# GENERAL_WKUP register map
Vendor: Texas Instruments
Peripheral module from a debugger description file (folder omap34xx).
Registers are 32-bit, access not given, reset 0x0 unless marked. A register's access mark holds for its fields unless they carry their own. Offsets are as the file gives them; lines under a group give offsets from that group; [hi:lo] are bit positions; {n}, {i} and the like mark numbered series; 'fields as' and 'values as' point back to an identical list; <NAME> marks a mode.

## GENERAL_WKUP
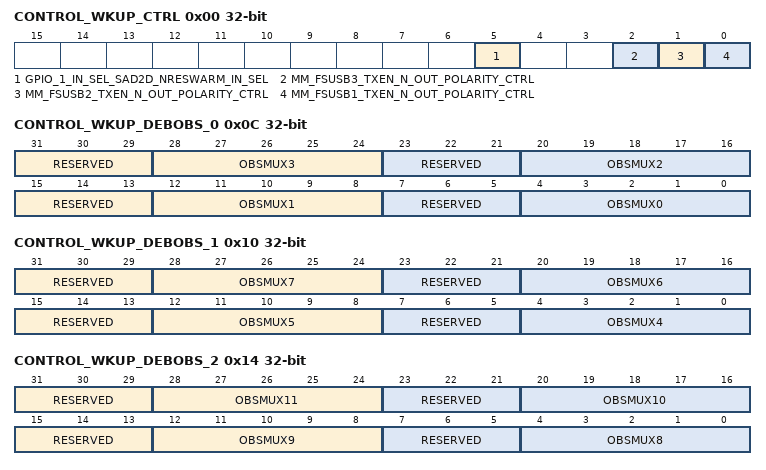
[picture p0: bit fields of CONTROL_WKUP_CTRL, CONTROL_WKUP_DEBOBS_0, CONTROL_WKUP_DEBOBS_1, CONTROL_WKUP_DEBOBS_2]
0x00 CONTROL_WKUP_CTRL access per field — USB TXEN polarity control and log modem warm reset source mux sel
  [5] GPIO_1_IN_SEL_SAD2D_NRESWARM_IN_SEL rw — Mux select for GPIO1/SAD2D_NRESWARM bit.
  [2] MM_FSUSB3_TXEN_N_OUT_POLARITY_CTRL rw — Polarity control for TXEN signal of multimode USB interface, port3.
    0=Active low; 1=Active high
  [1] MM_FSUSB2_TXEN_N_OUT_POLARITY_CTRL rw — Polarity control for TXEN signal of multimode USB interface, port2.
    0=Active low; 1=Active high
  [0] MM_FSUSB1_TXEN_N_OUT_POLARITY_CTRL rw — Polarity control for TXEN signal of multimode USB interface, port1.
    0=Active low; 1=Active high
0x0C CONTROL_WKUP_DEBOBS_0 — Select the WKUP domain set of signals to be observed for hw_dbg3, hw_dbg2, hw_dbg1, hw_dbg0
  [31:29] RESERVED ro — Read returns reset value.
  [8n+4:8n] OBSMUX{n} (n=0..3) — Select the set of signals to be observed for hw_dbg{n} (access Refer to)
  [23:21] RESERVED ro — Read returns reset value.
  [15:13] RESERVED ro — Read returns reset value.
  [7:5] RESERVED ro — Read returns reset value.
0x10 CONTROL_WKUP_DEBOBS_1 — Select the WKUP domain set of signals to be observed for hw_dbg7, hw_dbg6, hw_dbg5, hw_dbg4
  [31:29] RESERVED ro — Read returns reset value.
  [8n-28:8n-32] OBSMUX{n} (n=4..7) — Select the set of signals to be observed for hw_dbg{n} (access Refer to)
  [23:21] RESERVED ro — Read returns reset value.
  [15:13] RESERVED ro — Read returns reset value.
  [7:5] RESERVED ro — Read returns reset value.
0x14 CONTROL_WKUP_DEBOBS_2 — Select the WKUP domain set of signals to be observed for hw_dbg11 hw_dbg10, hw_dbg9, hw_dbg8
  [31:29] RESERVED ro — Read returns reset value.
  [8n-60:8n-64] OBSMUX{n} (n=8..11) — Select the set of signals to be observed for hw_dbg{n} (access Refer to)
  [23:21] RESERVED ro — Read returns reset value.
  [15:13] RESERVED ro — Read returns reset value.
  [7:5] RESERVED ro — Read returns reset value.
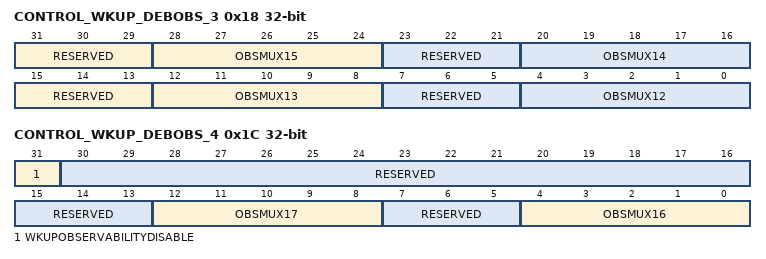
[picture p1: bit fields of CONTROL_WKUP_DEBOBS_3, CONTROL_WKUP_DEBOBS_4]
0x18 CONTROL_WKUP_DEBOBS_3 — Select the WKUP domain set of signals to be observed for hw_dbg15 hw_dbg14, hw_dbg13, hw_dbg12
  [31:29] RESERVED ro — Read returns reset value.
  [8n-92:8n-96] OBSMUX{n} (n=12..15) — Select the set of signals to be observed for hw_dbg{n} (access Refer to)
  [23:21] RESERVED ro — Read returns reset value.
  [15:13] RESERVED ro — Read returns reset value.
  [7:5] RESERVED ro — Read returns reset value.
0x1C CONTROL_WKUP_DEBOBS_4 — Select the WKUP domain set of signals to be observed for hw_dbg17, hw_dbg16
  [31] WKUPOBSERVABILITYDISABLE — Control the observability feature (access Refer to)
  [30:13] RESERVED ro — Read returns reset value.
  [12:8] OBSMUX17 — Select the set of signals to be observed for hw_dbg17 (access Refer to)
  [7:5] RESERVED ro — Read returns reset value.
  [4:0] OBSMUX16 — Select the set of signals to be observed for hw_dbg16 (access Refer to)
